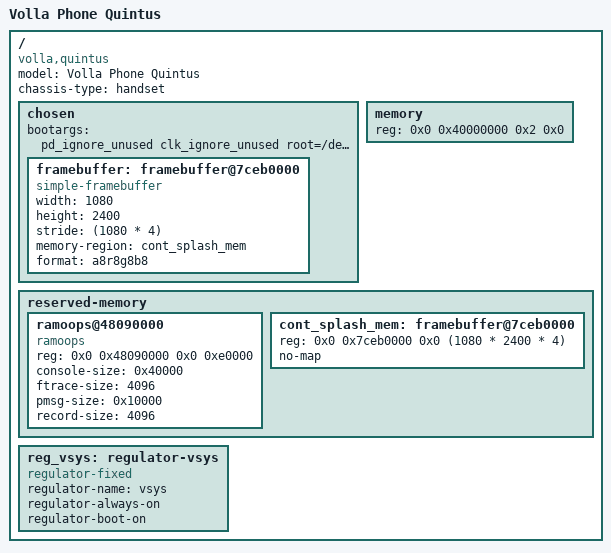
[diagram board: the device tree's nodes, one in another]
// SPDX-License-Identifier: GPL-2.0 OR BSD-3-Clause
/*
 * Volla Quintus device tree source
 *
 * Copyright (c) 2025, Ivaylo Ivanov <ivo.ivanov.ivanov1@gmail.com>
 */

/dts-v1/;
#include "mt6877v.dtsi"
#include <dt-bindings/gpio/gpio.h>
#include <dt-bindings/input/input.h>
#include <dt-bindings/interrupt-controller/irq.h>
#include <dt-bindings/regulator/mediatek,mt6360-regulator.h>
#include <dt-bindings/spmi/spmi.h>
#include <dt-bindings/pinctrl/mt6877-pinfunc.h>

/ {
	model = "Volla Phone Quintus";
	compatible = "volla,quintus", "mediatek,mt6877v";
	chassis-type = "handset";

	chosen {
		#address-cells = <2>;
		#size-cells = <2>;
		ranges;

		//stdout-path = "serial0:921600n8";
		//bootargs = "earlycon=uart8250,mmio32,0x11002000 keep_bootcon";
		bootargs = "pd_ignore_unused clk_ignore_unused root=/dev/ram0";

		framebuffer: framebuffer@7ceb0000 {
			compatible = "simple-framebuffer";
			width = <1080>;
			height = <2400>;
			stride = <(1080 * 4)>;
			memory-region = <&cont_splash_mem>;
			format = "a8r8g8b8";
		};
	};

	memory {
		device_type = "memory";
		reg = <0x0 0x40000000 0x2 0x0>;
	};
	
	reserved-memory {
		#address-cells = <2>;
		#size-cells = <2>;
		ranges;

		ramoops@48090000 {
			compatible = "ramoops";
			reg = <0x0 0x48090000 0x0 0xe0000>;
			console-size = <0x40000>;
			ftrace-size = <4096>;
			pmsg-size = <0x10000>;
			record-size = <4096>;
		};

		cont_splash_mem: framebuffer@7ceb0000 {
			reg = <0x0 0x7ceb0000 0x0 (1080 * 2400 * 4)>;
			no-map;
		};
	};

	/* system wide semi-regulated power rail from charger */
	reg_vsys: regulator-vsys {
		compatible = "regulator-fixed";
		regulator-name = "vsys";
		regulator-always-on;
		regulator-boot-on;
	};
};
#if 0
&i2c5 {
	clock-frequency = <400000>;
	pinctrl-0 = <&i2c5_pins>;
	pinctrl-names = "default";
	status = "okay";

	mt6360: pmic@34 {
		compatible = "mediatek,mt6360";
		reg = <0x34>;
		interrupt-controller;
		interrupts-extended = <&pio 4 IRQ_TYPE_EDGE_FALLING>;
		interrupt-names = "IRQB";
		#interrupt-cells = <1>;

		regulator {
			compatible = "mediatek,mt6360-regulator";
			LDO_VIN1-supply = <&reg_vsys>;
			LDO_VIN2-supply = <&reg_vsys>;
			LDO_VIN3-supply = <&reg_vsys>;

			mt6360_buck1: BUCK1 {
				regulator-name = "emi_vdd2";
				regulator-min-microvolt = <600000>;
				regulator-max-microvolt = <1800000>;
				regulator-allowed-modes = <MT6360_OPMODE_NORMAL
							   MT6360_OPMODE_LP
							   MT6360_OPMODE_ULP>;
				regulator-always-on;
			};

			mt6360_buck2: BUCK2 {
				regulator-name = "emi_vddq";
				regulator-min-microvolt = <300000>;
				regulator-max-microvolt = <1300000>;
				regulator-allowed-modes = <MT6360_OPMODE_NORMAL
							   MT6360_OPMODE_LP
							   MT6360_OPMODE_ULP>;
				regulator-always-on;
			};

			mt6360_ldo1: LDO1 {
				regulator-name = "mt6360_ldo1"; /* Test point */
				regulator-min-microvolt = <1200000>;
				regulator-max-microvolt = <3600000>;
				regulator-allowed-modes = <MT6360_OPMODE_NORMAL
							   MT6360_OPMODE_LP>;
			};

			mt6360_ldo2: LDO2 {
				regulator-name = "panel1_p1v8";
				regulator-min-microvolt = <1800000>;
				regulator-max-microvolt = <1800000>;
				regulator-allowed-modes = <MT6360_OPMODE_NORMAL
							   MT6360_OPMODE_LP>;
			};

			mt6360_ldo3: LDO3 {
				regulator-name = "vmc_pmu";
				regulator-min-microvolt = <1800000>;
				regulator-max-microvolt = <3300000>;
				regulator-allowed-modes = <MT6360_OPMODE_NORMAL
							   MT6360_OPMODE_LP>;
			};

			mt6360_ldo5: LDO5 {
				regulator-name = "vmch_pmu";
				regulator-min-microvolt = <3300000>;
				regulator-max-microvolt = <3300000>;
				regulator-allowed-modes = <MT6360_OPMODE_NORMAL
							   MT6360_OPMODE_LP>;
			};

			mt6360_ldo6: LDO6 {
				regulator-name = "mt6360_ldo6"; /* Test point */
				regulator-min-microvolt = <500000>;
				regulator-max-microvolt = <2100000>;
				regulator-allowed-modes = <MT6360_OPMODE_NORMAL
							   MT6360_OPMODE_LP>;
			};

			mt6360_ldo7: LDO7 {
				regulator-name = "emi_vmddr_en";
				regulator-min-microvolt = <1800000>;
				regulator-max-microvolt = <1800000>;
				regulator-allowed-modes = <MT6360_OPMODE_NORMAL
							   MT6360_OPMODE_LP>;
				regulator-always-on;
			};
		};
	};
};

&pio {
	mediatek,rsel-resistance-in-si-unit;
#if 0
	i2c0_pins: i2c0-default-pins {
		pins-bus {
			pinmux = <PINMUX_GPIO8__FUNC_SDA0>,
				 <PINMUX_GPIO9__FUNC_SCL0>;
			bias-disable;
			drive-strength-microamp = <1000>;
		};
	};

	i2c1_pins: i2c1-default-pins {
		pins-bus {
			pinmux = <PINMUX_GPIO10__FUNC_SDA1>,
				 <PINMUX_GPIO11__FUNC_SCL1>;
			bias-pull-up = <1000>;
			drive-strength-microamp = <1000>;
		};
	};

	i2c2_pins: i2c2-default-pins {
		pins-bus {
			pinmux = <PINMUX_GPIO12__FUNC_SDA2>,
				 <PINMUX_GPIO13__FUNC_SCL2>;
			bias-disable;
			drive-strength-microamp = <1000>;
		};
	};

	i2c3_pins: i2c3-default-pins {
		pins-bus {
			pinmux = <PINMUX_GPIO14__FUNC_SDA3>,
				 <PINMUX_GPIO15__FUNC_SCL3>;
			bias-pull-up = <1000>;
			drive-strength-microamp = <1000>;
		};
	};

	i2c4_pins: i2c4-default-pins {
		pins-bus {
			pinmux = <PINMUX_GPIO16__FUNC_SDA4>,
				 <PINMUX_GPIO17__FUNC_SCL4>;
			bias-pull-up = <1000>;
			drive-strength = <4>;
		};
	};
#endif
	i2c5_pins: i2c5-default-pins {
		pins-bus {
			pinmux = <PINMUX_GPIO132__FUNC_SCL5>,
				 <PINMUX_GPIO133__FUNC_SDA5>;
			bias-disable;
			drive-strength-microamp = <1000>;
		};
	};

};

&spmi {
	#address-cells = <2>;
	#size-cells = <0>;

	mt6315@6 {
		compatible = "mediatek,mt6315-regulator";
		reg = <0x6 SPMI_USID>;

		regulators {
			mt6315_6_vbuck1: vbuck1 {
				regulator-name = "Vbcpu";
				regulator-min-microvolt = <400000>;
				regulator-max-microvolt = <1193750>;
				regulator-enable-ramp-delay = <256>;
				regulator-ramp-delay = <6250>;
				regulator-allowed-modes = <0 1 2>;
				regulator-always-on;
			};
		};
	};

	mt6315@7 {
		compatible = "mediatek,mt6315-regulator";
		reg = <0x7 SPMI_USID>;

		regulators {
			mt6315_7_vbuck1: vbuck1 {
				regulator-name = "Vgpu";
				regulator-min-microvolt = <400000>;
				regulator-max-microvolt = <1193750>;
				regulator-enable-ramp-delay = <256>;
				regulator-ramp-delay = <6250>;
				regulator-allowed-modes = <0 1 2>;
			};
		};
	};
};

#endif
